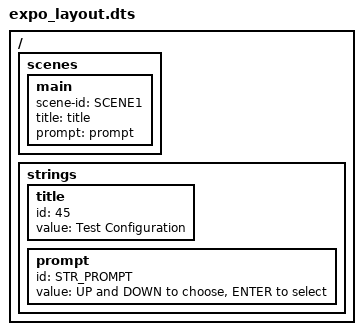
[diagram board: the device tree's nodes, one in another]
// SPDX-License-Identifier: GPL-2.0+
/*
 * Sample expo screen layout
 */

/dts-v1/;

/ {
	scenes {
		main {
			scene-id = <SCENE1>;
			title = "title";
			prompt = "prompt";
		};
	};

	strings {
		title {
			id = <45>;
			value = "Test Configuration";
		};

		prompt {
			id = <STR_PROMPT>;
			value = "UP and DOWN to choose, ENTER to select";
		};
	};
};
